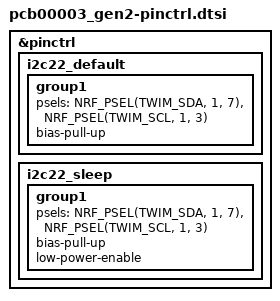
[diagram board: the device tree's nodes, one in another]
/*
 * Copyright (c) 2026 ByteExplain / JAC Dental
 * SPDX-License-Identifier: Apache-2.0
 *
 * PCB00003-TGM-SCHEM-REV10 sheet 2, ES4L15BA1:
 *   SDA P1.07, SCL P1.03
 */

&pinctrl {
	/* nRF54 TWIM does not enable the pad pull-ups. Without them SCL
	 * stays low, every transfer times out, and the green LED write
	 * never reaches the MAXM86161.
	 */
	i2c22_default: i2c22_default {
		group1 {
			psels = <NRF_PSEL(TWIM_SDA, 1, 7)>,
				<NRF_PSEL(TWIM_SCL, 1, 3)>;
			bias-pull-up;
		};
	};

	i2c22_sleep: i2c22_sleep {
		group1 {
			psels = <NRF_PSEL(TWIM_SDA, 1, 7)>,
				<NRF_PSEL(TWIM_SCL, 1, 3)>;
			bias-pull-up;
			low-power-enable;
		};
	};
};
